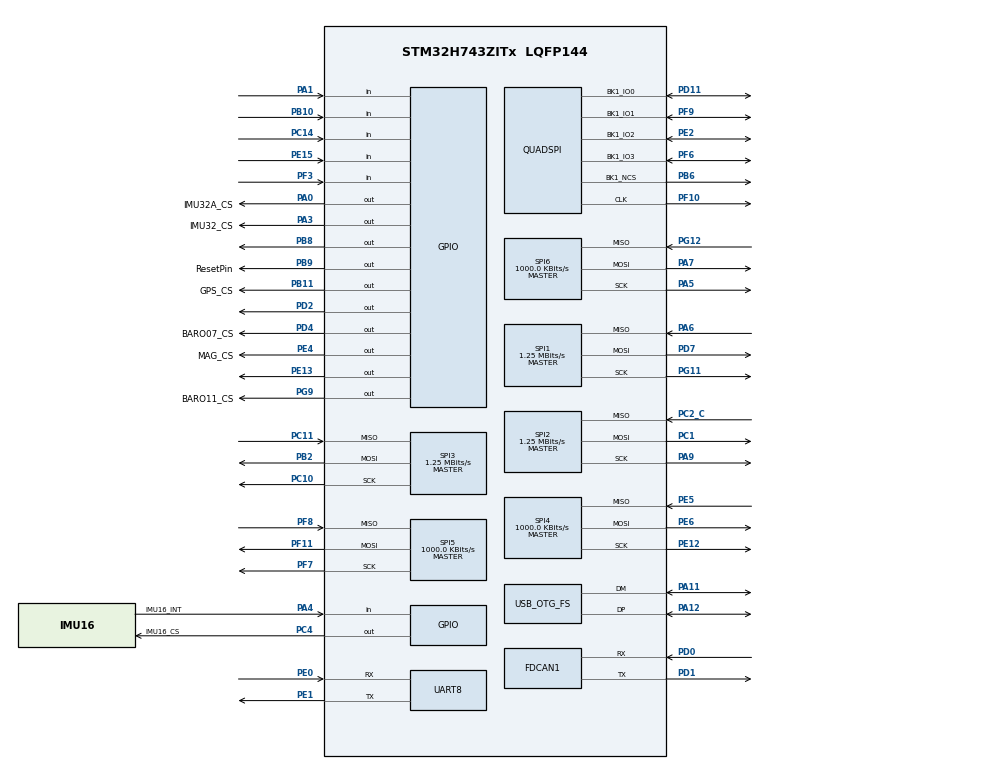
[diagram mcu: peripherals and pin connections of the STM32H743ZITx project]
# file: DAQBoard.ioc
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FDCAN1.AutoRetransmission=ENABLE
FDCAN1.CalculateBaudRateNominal=1000000
FDCAN1.CalculateTimeBitNominal=1000
FDCAN1.CalculateTimeQuantumNominal=25.0
FDCAN1.DataSyncJumpWidth=7
FDCAN1.DataTimeSeg1=8
FDCAN1.DataTimeSeg2=7
FDCAN1.FrameFormat=FDCAN_FRAME_FD_BRS
FDCAN1.NominalPrescaler=1
FDCAN1.NominalSyncJumpWidth=6
FDCAN1.NominalTimeSeg1=33
FDCAN1.NominalTimeSeg2=6
FDCAN1.RxBuffersNbr=0
FDCAN1.RxFifo0ElmtSize=FDCAN_DATA_BYTES_64
FDCAN1.RxFifo0ElmtsNbr=5
FDCAN1.TxElmtSize=FDCAN_DATA_BYTES_64
FDCAN1.TxFifoQueueElmtsNbr=5
FREERTOS.Tasks01=defaultTask,24,128,StartDefaultTask,Default,NULL,Dynamic,NULL,NULL
FREERTOS.configTOTAL_HEAP_SIZE=128000
FREERTOS.configUSE_NEWLIB_REENTRANT=1
FREERTOS.configUSE_TIMERS=1
Mcu.Family=STM32H7
Mcu.Name=STM32H743ZITx
Mcu.Package=LQFP144
NVIC.FDCAN1_IT0_IRQn=true\:5\:0\:false\:false\:true\:true\:true\:true\:true
NVIC.PriorityGroup=NVIC_PRIORITYGROUP_4
NVIC.TIM2_IRQn=true\:15\:0\:false\:false\:true\:false\:false\:true\:true
NVIC.TimeBase=TIM2_IRQn
NVIC.TimeBaseIP=TIM2
NVIC.UART8_IRQn=true\:5\:0\:false\:false\:true\:true\:true\:true\:true
PA0.GPIO_Label=IMU32A_CS
PA0.Signal=GPIO_Output
PA1.Signal=GPIO_Input
PA11.Mode=Device_Only
PA11.Signal=USB_OTG_FS_DM
PA12.Mode=Device_Only
PA12.Signal=USB_OTG_FS_DP
PA13\ (JTMS/SWDIO).Mode=Serial_Wire
PA13\ (JTMS/SWDIO).Signal=DEBUG_JTMS-SWDIO
PA14\ (JTCK/SWCLK).Mode=Serial_Wire
PA14\ (JTCK/SWCLK).Signal=DEBUG_JTCK-SWCLK
PA3.GPIO_Label=IMU32_CS
PA3.Signal=GPIO_Output
PA4.GPIO_Label=IMU16_INT
PA4.Signal=GPIO_Input
PA5.Mode=Full_Duplex_Master
PA5.Signal=SPI6_SCK
PA6.Mode=Full_Duplex_Master
PA6.Signal=SPI1_MISO
PA7.Mode=Full_Duplex_Master
PA7.Signal=SPI6_MOSI
PA9.Mode=Full_Duplex_Master
PA9.Signal=SPI2_SCK
PB10.Signal=GPIO_Input
PB11.GPIO_Label=GPS_CS
PB11.Signal=GPIO_Output
PB15.Signal=S_TIM12_CH2
PB2.Mode=Full_Duplex_Master
PB2.Signal=SPI3_MOSI
PB3\ (JTDO/TRACESWO).Signal=DEBUG_JTDO-SWO
PB6.Mode=Single Bank 1
PB6.Signal=QUADSPI_BK1_NCS
PB8.Signal=GPIO_Output
PB9.GPIO_Label=ResetPin
PB9.Signal=GPIO_Output
PC1.Mode=Full_Duplex_Master
PC1.Signal=SPI2_MOSI
PC10.Mode=Full_Duplex_Master
PC10.Signal=SPI3_SCK
PC11.Mode=Full_Duplex_Master
PC11.Signal=SPI3_MISO
PC14-OSC32_IN\ (OSC32_IN).Signal=GPIO_Input
PC2_C.Mode=Full_Duplex_Master
PC2_C.Signal=SPI2_MISO
PC4.GPIO_Label=IMU16_CS
PC4.Signal=GPIO_Output
PC8.Signal=S_TIM3_CH3
PD0.Mode=FDCAN_Activate
PD0.Signal=FDCAN1_RX
PD1.Mode=FDCAN_Activate
PD1.Signal=FDCAN1_TX
PD11.Mode=Single Bank 1
PD11.Signal=QUADSPI_BK1_IO0
PD2.Signal=GPIO_Output
PD4.GPIO_Label=BARO07_CS
PD4.Signal=GPIO_Output
PD7.Mode=Full_Duplex_Master
PD7.Signal=SPI1_MOSI
PE0.Mode=Asynchronous
PE0.Signal=UART8_RX
PE1.Mode=Asynchronous
PE1.Signal=UART8_TX
PE12.Mode=Full_Duplex_Master
PE12.Signal=SPI4_SCK
PE13.Signal=GPIO_Output
PE15.Signal=GPIO_Input
PE2.Mode=Single Bank 1
PE2.Signal=QUADSPI_BK1_IO2
PE4.GPIO_Label=MAG_CS
PE4.Signal=GPIO_Output
PE5.Mode=Full_Duplex_Master
PE5.Signal=SPI4_MISO
PE6.Mode=Full_Duplex_Master
PE6.Signal=SPI4_MOSI
PF10.Mode=Single Bank 1
PF10.Signal=QUADSPI_CLK
PF11.Mode=Full_Duplex_Master
PF11.Signal=SPI5_MOSI
PF3.Signal=GPIO_Input
PF6.Mode=Single Bank 1
PF6.Signal=QUADSPI_BK1_IO3
PF7.Mode=Full_Duplex_Master
PF7.Signal=SPI5_SCK
PF8.Mode=Full_Duplex_Master
PF8.Signal=SPI5_MISO
PF9.Mode=Single Bank 1
PF9.Signal=QUADSPI_BK1_IO1
PG11.Mode=Full_Duplex_Master
PG11.Signal=SPI1_SCK
PG12.Mode=Full_Duplex_Master
PG12.Signal=SPI6_MISO
PG6.Signal=DCMI_D12
PG9.GPIO_Label=BARO11_CS
PG9.Signal=GPIO_Output
ProjectManager.HeapSize=0x200
ProjectManager.StackSize=0x400
ProjectManager.TargetToolchain=STM32CubeIDE
QUADSPI.ClockPrescaler=255
QUADSPI.FlashSize=26
RCC.ADCFreq_Value=129000000
RCC.APB1Freq_Value=32000000
RCC.APB2Freq_Value=32000000
RCC.APB3Freq_Value=64000000
RCC.APB4Freq_Value=32000000
RCC.CortexFreq_Value=64000000
RCC.D2PPRE1=RCC_APB1_DIV2
RCC.D2PPRE2=RCC_APB2_DIV2
RCC.D3PPRE=RCC_APB4_DIV2
RCC.DIVM1=4
RCC.DIVN1=10
RCC.DIVQ1=4
RCC.HCLKFreq_Value=64000000
RCC.PLL2FRACN=0
RCC.PLL3FRACN=0
RCC.PLLFRACN=0
RCC.PLLSourceVirtual=RCC_PLLSOURCE_HSI
RCC.SYSCLKFreq_VALUE=64000000
RCC.USBCLockSelection=RCC_USBCLKSOURCE_HSI48
RCC.USBFreq_Value=48000000
SH.S_TIM12_CH2.0=TIM12_CH2
SH.S_TIM3_CH3.0=TIM3_CH3
SPI1.BaudRatePrescaler=SPI_BAUDRATEPRESCALER_32
SPI1.CalculateBaudRate=1.25 MBits/s
SPI1.DataSize=SPI_DATASIZE_8BIT
SPI1.Direction=SPI_DIRECTION_2LINES
SPI1.Mode=SPI_MODE_MASTER
SPI1.VirtualType=VM_MASTER
SPI2.BaudRatePrescaler=SPI_BAUDRATEPRESCALER_32
SPI2.CalculateBaudRate=1.25 MBits/s
SPI2.DataSize=SPI_DATASIZE_8BIT
SPI2.Direction=SPI_DIRECTION_2LINES
SPI2.Mode=SPI_MODE_MASTER
SPI2.VirtualType=VM_MASTER
SPI3.BaudRatePrescaler=SPI_BAUDRATEPRESCALER_32
SPI3.CalculateBaudRate=1.25 MBits/s
SPI3.DataSize=SPI_DATASIZE_8BIT
SPI3.Direction=SPI_DIRECTION_2LINES
SPI3.Mode=SPI_MODE_MASTER
SPI3.VirtualType=VM_MASTER
SPI4.BaudRatePrescaler=SPI_BAUDRATEPRESCALER_32
SPI4.CalculateBaudRate=1000.0 KBits/s
SPI4.DataSize=SPI_DATASIZE_8BIT
SPI4.Direction=SPI_DIRECTION_2LINES
SPI4.Mode=SPI_MODE_MASTER
SPI4.VirtualType=VM_MASTER
SPI5.BaudRatePrescaler=SPI_BAUDRATEPRESCALER_32
SPI5.CalculateBaudRate=1000.0 KBits/s
SPI5.DataSize=SPI_DATASIZE_8BIT
SPI5.Direction=SPI_DIRECTION_2LINES
SPI5.Mode=SPI_MODE_MASTER
SPI5.VirtualType=VM_MASTER
SPI6.BaudRatePrescaler=SPI_BAUDRATEPRESCALER_32
SPI6.CalculateBaudRate=1000.0 KBits/s
SPI6.DataSize=SPI_DATASIZE_8BIT
SPI6.Direction=SPI_DIRECTION_2LINES
SPI6.Mode=SPI_MODE_MASTER
SPI6.VirtualType=VM_MASTER
USB_OTG_FS.VirtualMode=Device_Only
VP_CRC_VS_CRC.Mode=CRC_Activate
VP_FREERTOS_VS_CMSIS_V2.Mode=CMSIS_V2
VP_MEMORYMAP_VS_MEMORYMAP.Mode=CurAppReg
VP_RTC_VS_RTC_Activate.Mode=RTC_Enabled
VP_SYS_VS_tim2.Mode=TIM2
board=custom

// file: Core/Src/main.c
/* USER CODE BEGIN Header */
/**
  ******************************************************************************
  * @file           : main.c
  * @brief          : Main program body
  ******************************************************************************
  * @attention
  *
  * Copyright (c) 2025 STMicroelectronics.
  * All rights reserved.
  *
  * This software is licensed under terms that can be found in the LICENSE file
  * in the root directory of this software component.
  * If no LICENSE file comes with this software, it is provided AS-IS.
  *
  ******************************************************************************
  */
/* USER CODE END Header */
#include "main.h"
#include "cmsis_os.h"

/* USER CODE BEGIN Includes */
#include "RunInterface.hpp"
/* USER CODE END Includes */

CRC_HandleTypeDef hcrc;

FDCAN_HandleTypeDef hfdcan1;

QSPI_HandleTypeDef hqspi;

RTC_HandleTypeDef hrtc;

SPI_HandleTypeDef hspi1;
SPI_HandleTypeDef hspi2;
SPI_HandleTypeDef hspi3;
SPI_HandleTypeDef hspi4;
SPI_HandleTypeDef hspi5;
SPI_HandleTypeDef hspi6;

UART_HandleTypeDef huart8;

/* Definitions for defaultTask */
osThreadId_t defaultTaskHandle;
const osThreadAttr_t defaultTask_attributes = {
  .name = "defaultTask",
  .stack_size = 128 * 4,
  .priority = (osPriority_t) osPriorityNormal,
};

void SystemClock_Config(void);
static void MX_GPIO_Init(void);
static void MX_QUADSPI_Init(void);
static void MX_SPI1_Init(void);
static void MX_SPI2_Init(void);
static void MX_SPI3_Init(void);
static void MX_SPI4_Init(void);
static void MX_SPI5_Init(void);
static void MX_SPI6_Init(void);
static void MX_FDCAN1_Init(void);
static void MX_CRC_Init(void);
static void MX_UART8_Init(void);
static void MX_RTC_Init(void);
void StartDefaultTask(void *argument);

int main(void)
{

  /* USER CODE BEGIN 1 */
	SCB-> VTOR = FLASH_BASE;
  /* USER CODE END 1 */

  /* MCU Configuration--------------------------------------------------------*/

  /* Reset of all peripherals, Initializes the Flash interface and the Systick. */
  HAL_Init();

  /* Configure the system clock */
  SystemClock_Config();

  /* Initialize all configured peripherals */
  MX_GPIO_Init();
  MX_QUADSPI_Init();
  MX_SPI1_Init();
  MX_SPI2_Init();
  MX_SPI3_Init();
  MX_SPI4_Init();
  MX_SPI5_Init();
  MX_SPI6_Init();
  MX_FDCAN1_Init();
  MX_CRC_Init();
  MX_UART8_Init();
  MX_RTC_Init();
  /* USER CODE BEGIN 2 */
  __enable_irq();

  run_interface();
  #if 0
  /* USER CODE END 2 */

  /* Init scheduler */
  osKernelInitialize();

  /* Create the thread(s) */
  /* creation of defaultTask */
  defaultTaskHandle = osThreadNew(StartDefaultTask, NULL, &defaultTask_attributes);

  /* Start scheduler */
  osKernelStart();

  /* We should never get here as control is now taken by the scheduler */

  /* Infinite loop */
  while (1)
  {

    /* USER CODE BEGIN 3 */
  }
  #endif
  /* USER CODE END 3 */
}

void SystemClock_Config(void)
{
  RCC_OscInitTypeDef RCC_OscInitStruct = {0};
  RCC_ClkInitTypeDef RCC_ClkInitStruct = {0};

  /** Supply configuration update enable
  */
  HAL_PWREx_ConfigSupply(PWR_LDO_SUPPLY);

  /** Configure the main internal regulator output voltage
  */
  __HAL_PWR_VOLTAGESCALING_CONFIG(PWR_REGULATOR_VOLTAGE_SCALE3);

  while(!__HAL_PWR_GET_FLAG(PWR_FLAG_VOSRDY)) {}

  /** Initializes the RCC Oscillators according to the specified parameters
  * in the RCC_OscInitTypeDef structure.
  */
  RCC_OscInitStruct.OscillatorType = RCC_OSCILLATORTYPE_HSI48|RCC_OSCILLATORTYPE_HSI
                              |RCC_OSCILLATORTYPE_LSI;
  RCC_OscInitStruct.HSIState = RCC_HSI_DIV1;
  RCC_OscInitStruct.HSICalibrationValue = RCC_HSICALIBRATION_DEFAULT;
  RCC_OscInitStruct.LSIState = RCC_LSI_ON;
  RCC_OscInitStruct.HSI48State = RCC_HSI48_ON;
  RCC_OscInitStruct.PLL.PLLState = RCC_PLL_ON;
  RCC_OscInitStruct.PLL.PLLSource = RCC_PLLSOURCE_HSI;
  RCC_OscInitStruct.PLL.PLLM = 4;
  RCC_OscInitStruct.PLL.PLLN = 10;
  RCC_OscInitStruct.PLL.PLLP = 2;
  RCC_OscInitStruct.PLL.PLLQ = 4;
  RCC_OscInitStruct.PLL.PLLR = 2;
  RCC_OscInitStruct.PLL.PLLRGE = RCC_PLL1VCIRANGE_3;
  RCC_OscInitStruct.PLL.PLLVCOSEL = RCC_PLL1VCOMEDIUM;
  RCC_OscInitStruct.PLL.PLLFRACN = 0;
  if (HAL_RCC_OscConfig(&RCC_OscInitStruct) != HAL_OK)
  {
    Error_Handler();
  }

  /** Initializes the CPU, AHB and APB buses clocks
  */
  RCC_ClkInitStruct.ClockType = RCC_CLOCKTYPE_HCLK|RCC_CLOCKTYPE_SYSCLK
                              |RCC_CLOCKTYPE_PCLK1|RCC_CLOCKTYPE_PCLK2
                              |RCC_CLOCKTYPE_D3PCLK1|RCC_CLOCKTYPE_D1PCLK1;
  RCC_ClkInitStruct.SYSCLKSource = RCC_SYSCLKSOURCE_HSI;
  RCC_ClkInitStruct.SYSCLKDivider = RCC_SYSCLK_DIV1;
  RCC_ClkInitStruct.AHBCLKDivider = RCC_HCLK_DIV1;
  RCC_ClkInitStruct.APB3CLKDivider = RCC_APB3_DIV1;
  RCC_ClkInitStruct.APB1CLKDivider = RCC_APB1_DIV2;
  RCC_ClkInitStruct.APB2CLKDivider = RCC_APB2_DIV2;
  RCC_ClkInitStruct.APB4CLKDivider = RCC_APB4_DIV2;

  if (HAL_RCC_ClockConfig(&RCC_ClkInitStruct, FLASH_LATENCY_1) != HAL_OK)
  {
    Error_Handler();
  }
}

static void MX_CRC_Init(void)
{

  hcrc.Instance = CRC;
  hcrc.Init.DefaultPolynomialUse = DEFAULT_POLYNOMIAL_ENABLE;
  hcrc.Init.DefaultInitValueUse = DEFAULT_INIT_VALUE_ENABLE;
  hcrc.Init.InputDataInversionMode = CRC_INPUTDATA_INVERSION_NONE;
  hcrc.Init.OutputDataInversionMode = CRC_OUTPUTDATA_INVERSION_DISABLE;
  hcrc.InputDataFormat = CRC_INPUTDATA_FORMAT_BYTES;
  if (HAL_CRC_Init(&hcrc) != HAL_OK)
  {
    Error_Handler();
  }

}

static void MX_FDCAN1_Init(void)
{

  hfdcan1.Instance = FDCAN1;
  hfdcan1.Init.FrameFormat = FDCAN_FRAME_FD_BRS;
  hfdcan1.Init.Mode = FDCAN_MODE_NORMAL;
  hfdcan1.Init.AutoRetransmission = ENABLE;
  hfdcan1.Init.TransmitPause = DISABLE;
  hfdcan1.Init.ProtocolException = DISABLE;
  hfdcan1.Init.NominalPrescaler = 1;
  hfdcan1.Init.NominalSyncJumpWidth = 6;
  hfdcan1.Init.NominalTimeSeg1 = 33;
  hfdcan1.Init.NominalTimeSeg2 = 6;
  hfdcan1.Init.DataPrescaler = 1;
  hfdcan1.Init.DataSyncJumpWidth = 7;
  hfdcan1.Init.DataTimeSeg1 = 8;
  hfdcan1.Init.DataTimeSeg2 = 7;
  hfdcan1.Init.MessageRAMOffset = 0;
  hfdcan1.Init.StdFiltersNbr = 0;
  hfdcan1.Init.ExtFiltersNbr = 0;
  hfdcan1.Init.RxFifo0ElmtsNbr = 5;
  hfdcan1.Init.RxFifo0ElmtSize = FDCAN_DATA_BYTES_64;
  hfdcan1.Init.RxFifo1ElmtsNbr = 0;
  hfdcan1.Init.RxFifo1ElmtSize = FDCAN_DATA_BYTES_8;
  hfdcan1.Init.RxBuffersNbr = 0;
  hfdcan1.Init.RxBufferSize = FDCAN_DATA_BYTES_8;
  hfdcan1.Init.TxEventsNbr = 0;
  hfdcan1.Init.TxBuffersNbr = 0;
  hfdcan1.Init.TxFifoQueueElmtsNbr = 5;
  hfdcan1.Init.TxFifoQueueMode = FDCAN_TX_FIFO_OPERATION;
  hfdcan1.Init.TxElmtSize = FDCAN_DATA_BYTES_64;
  if (HAL_FDCAN_Init(&hfdcan1) != HAL_OK)
  {
    Error_Handler();
  }

}

static void MX_QUADSPI_Init(void)
{

  /* QUADSPI parameter configuration*/
  hqspi.Instance = QUADSPI;
  hqspi.Init.ClockPrescaler = 255;
  hqspi.Init.FifoThreshold = 1;
  hqspi.Init.SampleShifting = QSPI_SAMPLE_SHIFTING_NONE;
  hqspi.Init.FlashSize = 26;
  hqspi.Init.ChipSelectHighTime = QSPI_CS_HIGH_TIME_1_CYCLE;
  hqspi.Init.ClockMode = QSPI_CLOCK_MODE_0;
  hqspi.Init.FlashID = QSPI_FLASH_ID_1;
  hqspi.Init.DualFlash = QSPI_DUALFLASH_DISABLE;
  if (HAL_QSPI_Init(&hqspi) != HAL_OK)
  {
    Error_Handler();
  }

}

static void MX_RTC_Init(void)
{

  /** Initialize RTC Only
  */
  hrtc.Instance = RTC;
  hrtc.Init.HourFormat = RTC_HOURFORMAT_24;
  hrtc.Init.AsynchPrediv = 127;
  hrtc.Init.SynchPrediv = 255;
  hrtc.Init.OutPut = RTC_OUTPUT_DISABLE;
  hrtc.Init.OutPutPolarity = RTC_OUTPUT_POLARITY_HIGH;
  hrtc.Init.OutPutType = RTC_OUTPUT_TYPE_OPENDRAIN;
  hrtc.Init.OutPutRemap = RTC_OUTPUT_REMAP_NONE;
  if (HAL_RTC_Init(&hrtc) != HAL_OK)
  {
    Error_Handler();
  }

}

static void MX_SPI1_Init(void)
{

  /* SPI1 parameter configuration*/
  hspi1.Instance = SPI1;
  hspi1.Init.Mode = SPI_MODE_MASTER;
  hspi1.Init.Direction = SPI_DIRECTION_2LINES;
  hspi1.Init.DataSize = SPI_DATASIZE_8BIT;
  hspi1.Init.CLKPolarity = SPI_POLARITY_LOW;
  hspi1.Init.CLKPhase = SPI_PHASE_1EDGE;
  hspi1.Init.NSS = SPI_NSS_SOFT;
  hspi1.Init.BaudRatePrescaler = SPI_BAUDRATEPRESCALER_32;
  hspi1.Init.FirstBit = SPI_FIRSTBIT_MSB;
  hspi1.Init.TIMode = SPI_TIMODE_DISABLE;
  hspi1.Init.CRCCalculation = SPI_CRCCALCULATION_DISABLE;
  hspi1.Init.CRCPolynomial = 0x0;
  hspi1.Init.NSSPMode = SPI_NSS_PULSE_ENABLE;
  hspi1.Init.NSSPolarity = SPI_NSS_POLARITY_LOW;
  hspi1.Init.FifoThreshold = SPI_FIFO_THRESHOLD_01DATA;
  hspi1.Init.TxCRCInitializationPattern = SPI_CRC_INITIALIZATION_ALL_ZERO_PATTERN;
  hspi1.Init.RxCRCInitializationPattern = SPI_CRC_INITIALIZATION_ALL_ZERO_PATTERN;
  hspi1.Init.MasterSSIdleness = SPI_MASTER_SS_IDLENESS_00CYCLE;
  hspi1.Init.MasterInterDataIdleness = SPI_MASTER_INTERDATA_IDLENESS_00CYCLE;
  hspi1.Init.MasterReceiverAutoSusp = SPI_MASTER_RX_AUTOSUSP_DISABLE;
  hspi1.Init.MasterKeepIOState = SPI_MASTER_KEEP_IO_STATE_DISABLE;
  hspi1.Init.IOSwap = SPI_IO_SWAP_DISABLE;
  if (HAL_SPI_Init(&hspi1) != HAL_OK)
  {
    Error_Handler();
  }

}

static void MX_SPI2_Init(void)
{

  /* SPI2 parameter configuration*/
  hspi2.Instance = SPI2;
  hspi2.Init.Mode = SPI_MODE_MASTER;
  hspi2.Init.Direction = SPI_DIRECTION_2LINES;
  hspi2.Init.DataSize = SPI_DATASIZE_8BIT;
  hspi2.Init.CLKPolarity = SPI_POLARITY_LOW;
  hspi2.Init.CLKPhase = SPI_PHASE_1EDGE;
  hspi2.Init.NSS = SPI_NSS_SOFT;
  hspi2.Init.BaudRatePrescaler = SPI_BAUDRATEPRESCALER_32;
  hspi2.Init.FirstBit = SPI_FIRSTBIT_MSB;
  hspi2.Init.TIMode = SPI_TIMODE_DISABLE;
  hspi2.Init.CRCCalculation = SPI_CRCCALCULATION_DISABLE;
  hspi2.Init.CRCPolynomial = 0x0;
  hspi2.Init.NSSPMode = SPI_NSS_PULSE_ENABLE;
  hspi2.Init.NSSPolarity = SPI_NSS_POLARITY_LOW;
  hspi2.Init.FifoThreshold = SPI_FIFO_THRESHOLD_01DATA;
  hspi2.Init.TxCRCInitializationPattern = SPI_CRC_INITIALIZATION_ALL_ZERO_PATTERN;
  hspi2.Init.RxCRCInitializationPattern = SPI_CRC_INITIALIZATION_ALL_ZERO_PATTERN;
  hspi2.Init.MasterSSIdleness = SPI_MASTER_SS_IDLENESS_00CYCLE;
  hspi2.Init.MasterInterDataIdleness = SPI_MASTER_INTERDATA_IDLENESS_00CYCLE;
  hspi2.Init.MasterReceiverAutoSusp = SPI_MASTER_RX_AUTOSUSP_DISABLE;
  hspi2.Init.MasterKeepIOState = SPI_MASTER_KEEP_IO_STATE_DISABLE;
  hspi2.Init.IOSwap = SPI_IO_SWAP_DISABLE;
  if (HAL_SPI_Init(&hspi2) != HAL_OK)
  {
    Error_Handler();
  }

}

static void MX_SPI3_Init(void)
{

  /* SPI3 parameter configuration*/
  hspi3.Instance = SPI3;
  hspi3.Init.Mode = SPI_MODE_MASTER;
  hspi3.Init.Direction = SPI_DIRECTION_2LINES;
  hspi3.Init.DataSize = SPI_DATASIZE_8BIT;
  hspi3.Init.CLKPolarity = SPI_POLARITY_LOW;
  hspi3.Init.CLKPhase = SPI_PHASE_1EDGE;
  hspi3.Init.NSS = SPI_NSS_SOFT;
  hspi3.Init.BaudRatePrescaler = SPI_BAUDRATEPRESCALER_32;
  hspi3.Init.FirstBit = SPI_FIRSTBIT_MSB;
  hspi3.Init.TIMode = SPI_TIMODE_DISABLE;
  hspi3.Init.CRCCalculation = SPI_CRCCALCULATION_DISABLE;
  hspi3.Init.CRCPolynomial = 0x0;
  hspi3.Init.NSSPMode = SPI_NSS_PULSE_ENABLE;
  hspi3.Init.NSSPolarity = SPI_NSS_POLARITY_LOW;
  hspi3.Init.FifoThreshold = SPI_FIFO_THRESHOLD_01DATA;
  hspi3.Init.TxCRCInitializationPattern = SPI_CRC_INITIALIZATION_ALL_ZERO_PATTERN;
  hspi3.Init.RxCRCInitializationPattern = SPI_CRC_INITIALIZATION_ALL_ZERO_PATTERN;
  hspi3.Init.MasterSSIdleness = SPI_MASTER_SS_IDLENESS_00CYCLE;
  hspi3.Init.MasterInterDataIdleness = SPI_MASTER_INTERDATA_IDLENESS_00CYCLE;
  hspi3.Init.MasterReceiverAutoSusp = SPI_MASTER_RX_AUTOSUSP_DISABLE;
  hspi3.Init.MasterKeepIOState = SPI_MASTER_KEEP_IO_STATE_DISABLE;
  hspi3.Init.IOSwap = SPI_IO_SWAP_DISABLE;
  if (HAL_SPI_Init(&hspi3) != HAL_OK)
  {
    Error_Handler();
  }

}

static void MX_SPI4_Init(void)
{

  /* SPI4 parameter configuration*/
  hspi4.Instance = SPI4;
  hspi4.Init.Mode = SPI_MODE_MASTER;
  hspi4.Init.Direction = SPI_DIRECTION_2LINES;
  hspi4.Init.DataSize = SPI_DATASIZE_8BIT;
  hspi4.Init.CLKPolarity = SPI_POLARITY_LOW;
  hspi4.Init.CLKPhase = SPI_PHASE_1EDGE;
  hspi4.Init.NSS = SPI_NSS_SOFT;
  hspi4.Init.BaudRatePrescaler = SPI_BAUDRATEPRESCALER_32;
  hspi4.Init.FirstBit = SPI_FIRSTBIT_MSB;
  hspi4.Init.TIMode = SPI_TIMODE_DISABLE;
  hspi4.Init.CRCCalculation = SPI_CRCCALCULATION_DISABLE;
  hspi4.Init.CRCPolynomial = 0x0;
  hspi4.Init.NSSPMode = SPI_NSS_PULSE_ENABLE;
  hspi4.Init.NSSPolarity = SPI_NSS_POLARITY_LOW;
  hspi4.Init.FifoThreshold = SPI_FIFO_THRESHOLD_01DATA;
  hspi4.Init.TxCRCInitializationPattern = SPI_CRC_INITIALIZATION_ALL_ZERO_PATTERN;
  hspi4.Init.RxCRCInitializationPattern = SPI_CRC_INITIALIZATION_ALL_ZERO_PATTERN;
  hspi4.Init.MasterSSIdleness = SPI_MASTER_SS_IDLENESS_00CYCLE;
  hspi4.Init.MasterInterDataIdleness = SPI_MASTER_INTERDATA_IDLENESS_00CYCLE;
  hspi4.Init.MasterReceiverAutoSusp = SPI_MASTER_RX_AUTOSUSP_DISABLE;
  hspi4.Init.MasterKeepIOState = SPI_MASTER_KEEP_IO_STATE_DISABLE;
  hspi4.Init.IOSwap = SPI_IO_SWAP_DISABLE;
  if (HAL_SPI_Init(&hspi4) != HAL_OK)
  {
    Error_Handler();
  }

}

static void MX_SPI5_Init(void)
{

  /* SPI5 parameter configuration*/
  hspi5.Instance = SPI5;
  hspi5.Init.Mode = SPI_MODE_MASTER;
  hspi5.Init.Direction = SPI_DIRECTION_2LINES;
  hspi5.Init.DataSize = SPI_DATASIZE_8BIT;
  hspi5.Init.CLKPolarity = SPI_POLARITY_LOW;
  hspi5.Init.CLKPhase = SPI_PHASE_1EDGE;
  hspi5.Init.NSS = SPI_NSS_SOFT;
  hspi5.Init.BaudRatePrescaler = SPI_BAUDRATEPRESCALER_32;
  hspi5.Init.FirstBit = SPI_FIRSTBIT_MSB;
  hspi5.Init.TIMode = SPI_TIMODE_DISABLE;
  hspi5.Init.CRCCalculation = SPI_CRCCALCULATION_DISABLE;
  hspi5.Init.CRCPolynomial = 0x0;
  hspi5.Init.NSSPMode = SPI_NSS_PULSE_ENABLE;
  hspi5.Init.NSSPolarity = SPI_NSS_POLARITY_LOW;
  hspi5.Init.FifoThreshold = SPI_FIFO_THRESHOLD_01DATA;
  hspi5.Init.TxCRCInitializationPattern = SPI_CRC_INITIALIZATION_ALL_ZERO_PATTERN;
  hspi5.Init.RxCRCInitializationPattern = SPI_CRC_INITIALIZATION_ALL_ZERO_PATTERN;
  hspi5.Init.MasterSSIdleness = SPI_MASTER_SS_IDLENESS_00CYCLE;
  hspi5.Init.MasterInterDataIdleness = SPI_MASTER_INTERDATA_IDLENESS_00CYCLE;
  hspi5.Init.MasterReceiverAutoSusp = SPI_MASTER_RX_AUTOSUSP_DISABLE;
  hspi5.Init.MasterKeepIOState = SPI_MASTER_KEEP_IO_STATE_DISABLE;
  hspi5.Init.IOSwap = SPI_IO_SWAP_DISABLE;
  if (HAL_SPI_Init(&hspi5) != HAL_OK)
  {
    Error_Handler();
  }

}

static void MX_SPI6_Init(void)
{

  /* SPI6 parameter configuration*/
  hspi6.Instance = SPI6;
  hspi6.Init.Mode = SPI_MODE_MASTER;
  hspi6.Init.Direction = SPI_DIRECTION_2LINES;
  hspi6.Init.DataSize = SPI_DATASIZE_8BIT;
  hspi6.Init.CLKPolarity = SPI_POLARITY_LOW;
  hspi6.Init.CLKPhase = SPI_PHASE_1EDGE;
  hspi6.Init.NSS = SPI_NSS_SOFT;
  hspi6.Init.BaudRatePrescaler = SPI_BAUDRATEPRESCALER_32;
  hspi6.Init.FirstBit = SPI_FIRSTBIT_MSB;
  hspi6.Init.TIMode = SPI_TIMODE_DISABLE;
  hspi6.Init.CRCCalculation = SPI_CRCCALCULATION_DISABLE;
  hspi6.Init.CRCPolynomial = 0x0;
  hspi6.Init.NSSPMode = SPI_NSS_PULSE_ENABLE;
  hspi6.Init.NSSPolarity = SPI_NSS_POLARITY_LOW;
  hspi6.Init.FifoThreshold = SPI_FIFO_THRESHOLD_01DATA;
  hspi6.Init.TxCRCInitializationPattern = SPI_CRC_INITIALIZATION_ALL_ZERO_PATTERN;
  hspi6.Init.RxCRCInitializationPattern = SPI_CRC_INITIALIZATION_ALL_ZERO_PATTERN;
  hspi6.Init.MasterSSIdleness = SPI_MASTER_SS_IDLENESS_00CYCLE;
  hspi6.Init.MasterInterDataIdleness = SPI_MASTER_INTERDATA_IDLENESS_00CYCLE;
  hspi6.Init.MasterReceiverAutoSusp = SPI_MASTER_RX_AUTOSUSP_DISABLE;
  hspi6.Init.MasterKeepIOState = SPI_MASTER_KEEP_IO_STATE_DISABLE;
  hspi6.Init.IOSwap = SPI_IO_SWAP_DISABLE;
  if (HAL_SPI_Init(&hspi6) != HAL_OK)
  {
    Error_Handler();
  }

}

static void MX_UART8_Init(void)
{

  huart8.Instance = UART8;
  huart8.Init.BaudRate = 115200;
  huart8.Init.WordLength = UART_WORDLENGTH_8B;
  huart8.Init.StopBits = UART_STOPBITS_1;
  huart8.Init.Parity = UART_PARITY_NONE;
  huart8.Init.Mode = UART_MODE_TX_RX;
  huart8.Init.HwFlowCtl = UART_HWCONTROL_NONE;
  huart8.Init.OverSampling = UART_OVERSAMPLING_16;
  huart8.Init.OneBitSampling = UART_ONE_BIT_SAMPLE_DISABLE;
  huart8.Init.ClockPrescaler = UART_PRESCALER_DIV1;
  huart8.AdvancedInit.AdvFeatureInit = UART_ADVFEATURE_NO_INIT;
  if (HAL_UART_Init(&huart8) != HAL_OK)
  {
    Error_Handler();
  }
  if (HAL_UARTEx_SetTxFifoThreshold(&huart8, UART_TXFIFO_THRESHOLD_1_8) != HAL_OK)
  {
    Error_Handler();
  }
  if (HAL_UARTEx_SetRxFifoThreshold(&huart8, UART_RXFIFO_THRESHOLD_1_8) != HAL_OK)
  {
    Error_Handler();
  }
  if (HAL_UARTEx_DisableFifoMode(&huart8) != HAL_OK)
  {
    Error_Handler();
  }

}

static void MX_GPIO_Init(void)
{
  GPIO_InitTypeDef GPIO_InitStruct = {0};

  /* GPIO Ports Clock Enable */
  __HAL_RCC_GPIOE_CLK_ENABLE();
  __HAL_RCC_GPIOC_CLK_ENABLE();
  __HAL_RCC_GPIOF_CLK_ENABLE();
  __HAL_RCC_GPIOA_CLK_ENABLE();
  __HAL_RCC_GPIOB_CLK_ENABLE();
  __HAL_RCC_GPIOD_CLK_ENABLE();
  __HAL_RCC_GPIOG_CLK_ENABLE();

  /*Configure GPIO pin Output Level */
  HAL_GPIO_WritePin(GPIOE, MAG_CS_Pin|GPIO_PIN_13, GPIO_PIN_RESET);

  /*Configure GPIO pin Output Level */
  HAL_GPIO_WritePin(GPIOA, IMU32A_CS_Pin|IMU32_CS_Pin, GPIO_PIN_RESET);

  /*Configure GPIO pin Output Level */
  HAL_GPIO_WritePin(IMU16_CS_GPIO_Port, IMU16_CS_Pin, GPIO_PIN_RESET);

  /*Configure GPIO pin Output Level */
  HAL_GPIO_WritePin(GPIOB, GPS_CS_Pin|GPIO_PIN_8|ResetPin_Pin, GPIO_PIN_RESET);

  /*Configure GPIO pin Output Level */
  HAL_GPIO_WritePin(GPIOD, GPIO_PIN_2|BARO07_CS_Pin, GPIO_PIN_RESET);

  /*Configure GPIO pin Output Level */
  HAL_GPIO_WritePin(BARO11_CS_GPIO_Port, BARO11_CS_Pin, GPIO_PIN_RESET);

  /*Configure GPIO pins : MAG_CS_Pin PE13 */
  GPIO_InitStruct.Pin = MAG_CS_Pin|GPIO_PIN_13;
  GPIO_InitStruct.Mode = GPIO_MODE_OUTPUT_PP;
  GPIO_InitStruct.Pull = GPIO_NOPULL;
  GPIO_InitStruct.Speed = GPIO_SPEED_FREQ_LOW;
  HAL_GPIO_Init(GPIOE, &GPIO_InitStruct);

  /*Configure GPIO pin : PC14 */
  GPIO_InitStruct.Pin = GPIO_PIN_14;
  GPIO_InitStruct.Mode = GPIO_MODE_INPUT;
  GPIO_InitStruct.Pull = GPIO_NOPULL;
  HAL_GPIO_Init(GPIOC, &GPIO_InitStruct);

  /*Configure GPIO pin : PF3 */
  GPIO_InitStruct.Pin = GPIO_PIN_3;
  GPIO_InitStruct.Mode = GPIO_MODE_INPUT;
  GPIO_InitStruct.Pull = GPIO_NOPULL;
  HAL_GPIO_Init(GPIOF, &GPIO_InitStruct);

  /*Configure GPIO pins : IMU32A_CS_Pin IMU32_CS_Pin */
  GPIO_InitStruct.Pin = IMU32A_CS_Pin|IMU32_CS_Pin;
  GPIO_InitStruct.Mode = GPIO_MODE_OUTPUT_PP;
  GPIO_InitStruct.Pull = GPIO_NOPULL;
  GPIO_InitStruct.Speed = GPIO_SPEED_FREQ_LOW;
  HAL_GPIO_Init(GPIOA, &GPIO_InitStruct);

  /*Configure GPIO pins : PA1 IMU16_INT_Pin */
  GPIO_InitStruct.Pin = GPIO_PIN_1|IMU16_INT_Pin;
  GPIO_InitStruct.Mode = GPIO_MODE_INPUT;
  GPIO_InitStruct.Pull = GPIO_NOPULL;
  HAL_GPIO_Init(GPIOA, &GPIO_InitStruct);

  /*Configure GPIO pin : IMU16_CS_Pin */
  GPIO_InitStruct.Pin = IMU16_CS_Pin;
  GPIO_InitStruct.Mode = GPIO_MODE_OUTPUT_PP;
  GPIO_InitStruct.Pull = GPIO_NOPULL;
  GPIO_InitStruct.Speed = GPIO_SPEED_FREQ_LOW;
  HAL_GPIO_Init(IMU16_CS_GPIO_Port, &GPIO_InitStruct);

  /*Configure GPIO pin : PE15 */
  GPIO_InitStruct.Pin = GPIO_PIN_15;
  GPIO_InitStruct.Mode = GPIO_MODE_INPUT;
  GPIO_InitStruct.Pull = GPIO_NOPULL;
  HAL_GPIO_Init(GPIOE, &GPIO_InitStruct);

  /*Configure GPIO pin : PB10 */
  GPIO_InitStruct.Pin = GPIO_PIN_10;
  GPIO_InitStruct.Mode = GPIO_MODE_INPUT;
  GPIO_InitStruct.Pull = GPIO_NOPULL;
  HAL_GPIO_Init(GPIOB, &GPIO_InitStruct);

  /*Configure GPIO pins : GPS_CS_Pin PB8 ResetPin_Pin */
  GPIO_InitStruct.Pin = GPS_CS_Pin|GPIO_PIN_8|ResetPin_Pin;
  GPIO_InitStruct.Mode = GPIO_MODE_OUTPUT_PP;
  GPIO_InitStruct.Pull = GPIO_NOPULL;
  GPIO_InitStruct.Speed = GPIO_SPEED_FREQ_LOW;
  HAL_GPIO_Init(GPIOB, &GPIO_InitStruct);

  /*Configure GPIO pin : PB15 */
  GPIO_InitStruct.Pin = GPIO_PIN_15;
  GPIO_InitStruct.Mode = GPIO_MODE_AF_PP;
  GPIO_InitStruct.Pull = GPIO_NOPULL;
  GPIO_InitStruct.Speed = GPIO_SPEED_FREQ_LOW;
  GPIO_InitStruct.Alternate = GPIO_AF2_TIM12;
  HAL_GPIO_Init(GPIOB, &GPIO_InitStruct);

  /*Configure GPIO pin : PG6 */
  GPIO_InitStruct.Pin = GPIO_PIN_6;
  GPIO_InitStruct.Mode = GPIO_MODE_AF_PP;
  GPIO_InitStruct.Pull = GPIO_NOPULL;
  GPIO_InitStruct.Speed = GPIO_SPEED_FREQ_LOW;
  GPIO_InitStruct.Alternate = GPIO_AF13_DCMI;
  HAL_GPIO_Init(GPIOG, &GPIO_InitStruct);

  /*Configure GPIO pin : PC8 */
  GPIO_InitStruct.Pin = GPIO_PIN_8;
  GPIO_InitStruct.Mode = GPIO_MODE_AF_PP;
  GPIO_InitStruct.Pull = GPIO_NOPULL;
  GPIO_InitStruct.Speed = GPIO_SPEED_FREQ_LOW;
  GPIO_InitStruct.Alternate = GPIO_AF2_TIM3;
  HAL_GPIO_Init(GPIOC, &GPIO_InitStruct);

  /*Configure GPIO pins : PD2 BARO07_CS_Pin */
  GPIO_InitStruct.Pin = GPIO_PIN_2|BARO07_CS_Pin;
  GPIO_InitStruct.Mode = GPIO_MODE_OUTPUT_PP;
  GPIO_InitStruct.Pull = GPIO_NOPULL;
  GPIO_InitStruct.Speed = GPIO_SPEED_FREQ_LOW;
  HAL_GPIO_Init(GPIOD, &GPIO_InitStruct);

  /*Configure GPIO pin : BARO11_CS_Pin */
  GPIO_InitStruct.Pin = BARO11_CS_Pin;
  GPIO_InitStruct.Mode = GPIO_MODE_OUTPUT_PP;
  GPIO_InitStruct.Pull = GPIO_NOPULL;
  GPIO_InitStruct.Speed = GPIO_SPEED_FREQ_LOW;
  HAL_GPIO_Init(BARO11_CS_GPIO_Port, &GPIO_InitStruct);

  /*AnalogSwitch Config */
  HAL_SYSCFG_AnalogSwitchConfig(SYSCFG_SWITCH_PA0, SYSCFG_SWITCH_PA0_CLOSE);

}

void StartDefaultTask(void *argument)
{
  for(;;)
  {
    osDelay(1);
  }
}

void HAL_TIM_PeriodElapsedCallback(TIM_HandleTypeDef *htim)
{
  if (htim->Instance == TIM2)
  {
    HAL_IncTick();
  }
}

void Error_Handler(void)
{
  __disable_irq();
  while (1)
  {
  }
}

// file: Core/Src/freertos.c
/* USER CODE BEGIN Header */
/**
  ******************************************************************************
  * File Name          : freertos.c
  * Description        : Code for freertos applications
  ******************************************************************************
  * @attention
  *
  * Copyright (c) 2025 STMicroelectronics.
  * All rights reserved.
  *
  * This software is licensed under terms that can be found in the LICENSE file
  * in the root directory of this software component.
  * If no LICENSE file comes with this software, it is provided AS-IS.
  *
  ******************************************************************************
  */
/* USER CODE END Header */

#include "FreeRTOS.h"
#include "task.h"
#include "main.h"

/* GetIdleTaskMemory prototype (linked to static allocation support) */
void vApplicationGetIdleTaskMemory( StaticTask_t **ppxIdleTaskTCBBuffer, StackType_t **ppxIdleTaskStackBuffer, uint32_t *pulIdleTaskStackSize );

/* GetTimerTaskMemory prototype (linked to static allocation support) */
void vApplicationGetTimerTaskMemory( StaticTask_t **ppxTimerTaskTCBBuffer, StackType_t **ppxTimerTaskStackBuffer, uint32_t *pulTimerTaskStackSize );

/* USER CODE BEGIN GET_IDLE_TASK_MEMORY */
static StaticTask_t xIdleTaskTCBBuffer;
static StackType_t xIdleStack[configMINIMAL_STACK_SIZE];
static StaticTask_t xTimerTaskTCBBuffer;
static StackType_t xTimerStack[configTIMER_TASK_STACK_DEPTH];

void vApplicationGetIdleTaskMemory( StaticTask_t **ppxIdleTaskTCBBuffer, StackType_t **ppxIdleTaskStackBuffer, uint32_t *pulIdleTaskStackSize )
{
  *ppxIdleTaskTCBBuffer = &xIdleTaskTCBBuffer;
  *ppxIdleTaskStackBuffer = &xIdleStack[0];
  *pulIdleTaskStackSize = configMINIMAL_STACK_SIZE;
  /* place for user code */
}

void vApplicationGetTimerTaskMemory( StaticTask_t **ppxTimerTaskTCBBuffer, StackType_t **ppxTimerTaskStackBuffer, uint32_t *pulTimerTaskStackSize )
{
  *ppxTimerTaskTCBBuffer = &xTimerTaskTCBBuffer;
  *ppxTimerTaskStackBuffer = &xTimerStack[0];
  *pulTimerTaskStackSize = configTIMER_TASK_STACK_DEPTH;
}
/* USER CODE END GET_IDLE_TASK_MEMORY */

/* USER CODE END GET_TIMER_TASK_MEMORY */
